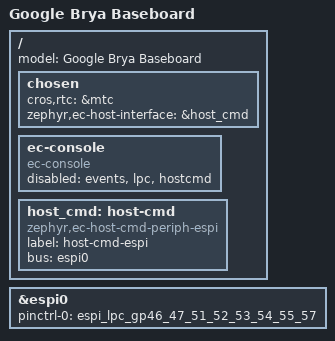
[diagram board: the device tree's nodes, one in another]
/* Copyright 2022 The Chromium OS Authors. All rights reserved.
 * Use of this source code is governed by a BSD-style license that can be
 * found in the LICENSE file.
 */

/ {
	model = "Google Brya Baseboard";

	chosen {
		cros,rtc = &mtc;
		zephyr,ec-host-interface = &host_cmd;
	};

	ec-console {
		compatible = "ec-console";
		disabled = "events", "lpc", "hostcmd";
	};

	host_cmd: host-cmd {
		compatible = "zephyr,ec-host-cmd-periph-espi";
		label = "host-cmd-espi";
		bus = <&espi0>;
	};
};

/* host interface */
&espi0 {
	status = "okay";
	pinctrl-0 = <&espi_lpc_gp46_47_51_52_53_54_55_57>;
	pinctrl-names = "default";
};
